# M3351 register map
File version: 1.0
Registers are 32-bit, read-write, reset 0x0 unless marked. A register's access mark holds for its fields unless they carry their own. Offsets are from the block's base; [hi:lo] are bit positions; {n}, {i} and the like mark numbered series.

## EBI_NS — EBINS Register Map
Base 0x50010000
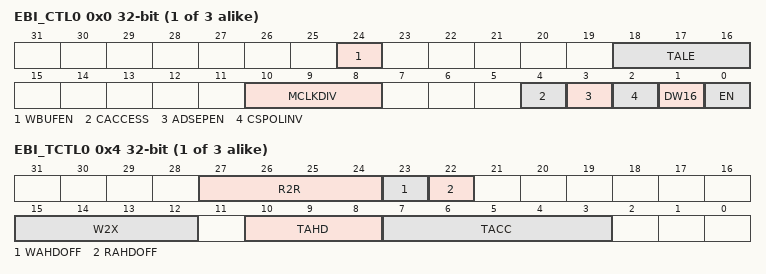
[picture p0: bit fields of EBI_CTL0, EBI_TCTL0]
{0x0+0x10*i} EBI_CTL{i} (i=0..2) — External Bus Interface Bank{i} Control Register
  [24] WBUFEN — EBI Write Buffer Enable Bit. Note: This bit is only available in EBI_CTL0 register.
    0=EBI write buffer Disabled; 1=EBI write buffer Enabled
  [18:16] TALE — Extend Time of ALE. The EBI_ALE high pulse period (tALE) to latch the address can be controlled by TALE. Note: This field is only available in EBI_CTL0 register.
  [10:8] MCLKDIV — External Output Clock Divider. The frequency of EBI output clock (MCLK) is controlled by MCLKDIV as follow:
    0=HCLK/1; 1=HCLK/2; 2=HCLK/4; 3=HCLK/8; 4=HCLK/16; 5=HCLK/32; 6=HCLK/64; 7=HCLK/128
  [4] CACCESS — Continuous Data Access Mode. When continuous access mode enabled, the tASU, tALE and tLHD cycles are bypass for continuous data transfer request.
    0=Continuous data access mode Disabled; 1=Continuous data access mode Enabled
  [3] ADSEPEN — EBI Address/Data Bus Separate Mode Enable Bit
    0=Address/Data Bus Separate Mode Disabled; 1=Address/Data Bus Separate Mode Enabled
  [2] CSPOLINV — Chip Select Pin Polar Inverse. This bit defines the active level of EBI chip select pin (EBI_nCS).
    0=Chip select pin (EBI_nCS) is active low; 1=Chip select pin (EBI_nCS) is active high
  [1] DW16 — EBI Data Width 16-bit Select. This bit defines if the EBI data width is 8-bit or 16-bit.
    0=EBI data width is 8-bit; 1=EBI data width is 16-bit
  [0] EN — EBI Enable Bit. This bit is the functional enable bit for EBI.
    0=EBI function Disabled; 1=EBI function Enabled
{0x4+0x10*i} EBI_TCTL{i} (i=0..2) — External Bus Interface Bank{i} Timing Control Register
  [27:24] R2R — Idle Cycle Between Read-to-read. This field defines the number of R2R idle cycle. When read action is finished and the next action is going to read, R2R idle cycle is inserted and EBI_nCS return to idle state.
  [23] WAHDOFF — Access Hold Time Disable Control When Write
    0=Data Access Hold Time (tAHD) during EBI writing Enabled; 1=Data Access Hold Time (tAHD) during EBI writing Disabled
  [22] RAHDOFF — Access Hold Time Disable Control When Read
    0=Data Access Hold Time (tAHD) during EBI reading Enabled; 1=Data Access Hold Time (tAHD) during EBI reading Disabled
  [15:12] W2X — Idle Cycle After Write. This field defines the number of W2X idle cycle. When write action is finished, W2X idle cycle is inserted and EBI_nCS return to idle state.
  [10:8] TAHD — EBI Data Access Hold Time. TAHD defines data access hold time (tAHD).
  [7:3] TACC — EBI Data Access Time. TACC defines data access time (tACC).

## DAC_NS — DAC Register Map
Base 0x50047000
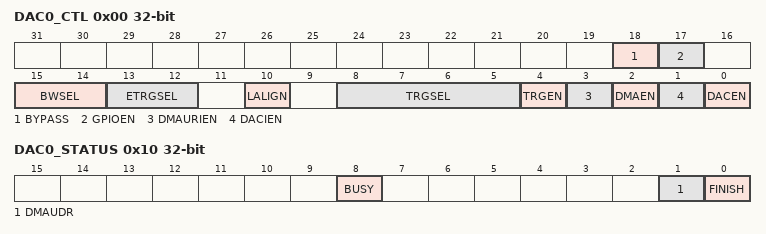
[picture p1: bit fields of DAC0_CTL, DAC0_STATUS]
0x00 DAC0_CTL — DAC0 Control Register
  [18] BYPASS — Bypass Buffer Mode
    0=Output voltage buffer Enabled; 1=Output voltage buffer Disabled
  [17] GPIOEN — GPIO Mode Enable Bit
    0=GPIO pin can output DAC0_OUT voltage; 1=GPIO pin can be used as other MFP
  [15:14] BWSEL — DAC Data Bit-width Selection
    0=Data is 12 bits; 1=Data is 8 bits
  [13:12] ETRGSEL — External Pin Trigger Selection
    0=Low level trigger; 1=High level trigger; 2=Falling edge trigger; 3=Rising edge trigger
  [10] LALIGN — DAC Data Left-aligned Enabled Bit
    0=Right alignment; 1=Left alignment
  [8:5] TRGSEL — Trigger Source Selection
    0=Software trigger; 1=External pin DAC0_ST trigger; {v}=Timer {v-2} trigger (v=2..5); 8=PWM0 trigger; 9=PWM1 trigger
  [4] TRGEN — Trigger Mode Enable Bit
    0=DAC event trigger mode Disabled; 1=DAC event trigger mode Enabled
  [3] DMAURIEN — DMA Under-run Interrupt Enable Bit
    0=DMA under-run interrupt Disabled; 1=DMA under-run interrupt Enabled
  [2] DMAEN — DMA Mode Enable Bit
    0=DMA mode Disabled; 1=DMA mode Enabled
  [1] DACIEN — DAC Interrupt Enable Bit
    0=DAC interrupt Disabled; 1=DAC interrupt Enabled
  [0] DACEN — DAC Enable Bit
    0=DAC Disabled; 1=DAC Enabled
0x04 DAC0_SWTRG — DAC0 Software Trigger Control Register
  [0] SWTRG — Software Trigger. Note: User writes this bit to generate one shot pulse and it is cleared to 0 by hardware automatically; reading this bit will always get 0.
    0=Software trigger Disabled; 1=Software trigger Enabled
0x08 DAC0_DAT — DAC0 Data Holding Register
  [15:0] DACDAT — DAC0 12-bit Holding Data. These bits are written by user software which specifies 12-bit conversion data for DAC output. The unused bits (DAC_DAT[3:0] in left-alignment mode and DAC_DAT[15:12] in right alignment mode) are ignored by DAC controller hardware. 12 bit left alignment: user has to load data into DAC_DAT[15:4] bits. 12 bit right alignment: user has to load data into DAC_DAT[11:0] bits.
0x0C DAC0_DATOUT ro — DAC0 Data Output Register
  [11:0] DATOUT — DAC 12-bit Output Data. These bits are current digital data for DAC output conversion. It is loaded from DAC_DAT register and user cannot write it directly.
0x10 DAC0_STATUS
  [8] BUSY — DAC Busy Flag (Read Only)
    0=DAC is ready for next conversion; 1=DAC is busy in conversion
  [1] DMAUDR — DMA Under-run Interrupt Flag. Note: User writes 1 to clear this bit.
    0=No DMA under-run error condition occurred; 1=DMA under-run error condition occurred
  [0] FINISH — DAC Conversion Complete Finish Flag. Note: This bit is set to 1 when conversion time counter counts to SETTLET. It is cleared to 0 when DAC starts a new conversion. User writes 1 to clear this bit to 0.
    0=DAC is in conversion state; 1=DAC conversion finish
0x14 DAC0_TCTL — DAC0 Timing Control Register
  [9:0] SETTLET — DAC Output Settling Time. User software needs to write appropriate value to these bits to meet DAC conversion settling time based on PCLK (APB clock) speed. For example, DAC controller clock speed is 72 MHz and DAC conversion settling time is 1 us, SETTLETvalue must be greater than 0x48.
